# PIC32CK1012SG00048 device description
Architecture: CORTEX-M33; Family: PIC32CK; Series: PIC32CKSG00
Registers are 32-bit, read-write, reset 0x0 unless marked. A register's access mark holds for its fields unless they carry their own. Offsets are from the block's base; [hi:lo] are bit positions; 'fields as' and 'values as' point back to an identical list.

## PCC — Parallel Capture Controller
Instances: PCC 0x45018000
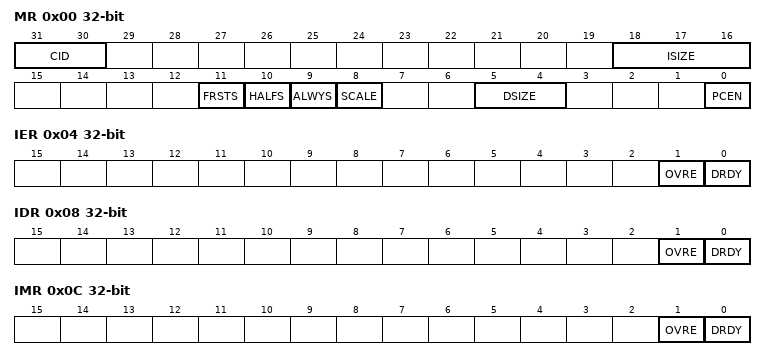
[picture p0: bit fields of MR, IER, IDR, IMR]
0x00 MR — Mode Register
  [31:30] CID — Clear If Disabled
  [18:16] ISIZE — Input Data Size
  [11] FRSTS — First sample
  [10] HALFS — Half Sampling
  [9] ALWYS — Always Sampling
  [8] SCALE — Scale data
  [5:4] DSIZE — Data size
  [0] PCEN — Parallel Capture Enable
0x04 IER wo (atomic set of IMR) — Interrupt Enable Register
  [1] OVRE — Overrun Error Interrupt Enable
  [0] DRDY — Data Ready Interrupt Enable
0x08 IDR wo (atomic clear of IMR) — Interrupt Disable Register
  [1] OVRE — Overrun Error Interrupt Disable
  [0] DRDY — Data Ready Interrupt Disable
0x0C IMR ro — Interrupt Mask Register
  [1] OVRE — Overrun Error Interrupt Mask
  [0] DRDY — Data Ready Interrupt Mask
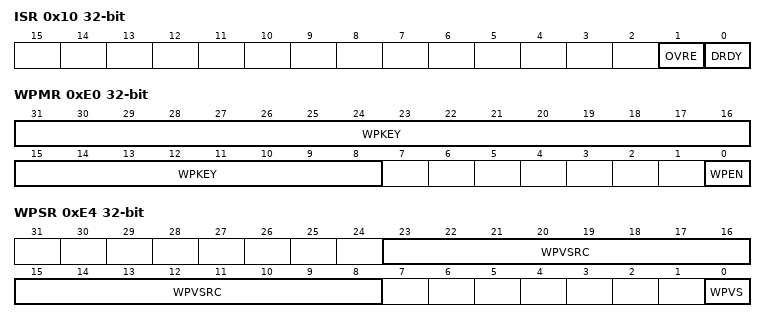
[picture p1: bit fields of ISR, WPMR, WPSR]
0x10 ISR ro — Interrupt Status Register
  [1] OVRE — Overrun Error Interrupt Status
  [0] DRDY — Data Ready Interrupt Status
0x14 RHR ro — Reception Holding Register
  [31:0] RDATA — Reception Data
0xE0 WPMR — Write Protection Mode Register
  [31:8] WPKEY — Write Protection Key
  [0] WPEN — Write Protection Enable
0xE4 WPSR ro — Write Protection Status Register
  [23:8] WPVSRC — Write Protection Violation Status
  [0] WPVS — Write Protection Violation Source

## PM — Power Manager
Instances: PM 0x44006000
0x00 CTRLA 8-bit — Control A
  [2] IORET — I/O Retention
    0=NOIORET (When the device exits the HIBERNATE or BACKUP mode, the I/O line configuration are released.); 1=IORET (When the device exits the HIBERNATE or BACKUP mode, the I/O line configuration are stretched.)
0x01 SLEEPCFG 8-bit reset 0x2 — Sleep Configuration
  [2:0] SLEEPMODE
    2=IDLE (CPU, AHB and APB clocks are OFF); 4=STANDBY (All Clocks are OFF); 5=HIBERNATE (Backup domain is ON as well as some PDRAMs); 6=BACKUP (Only Backup domain is powered ON); 7=OFF (All power domains are powered OFF)
0x04 INTENCLR 8-bit (atomic clear) — Interrupt Enable Clear
  [0] SLEEPRDY — Backup Sleep Mode Entry Ready Enable
0x05 INTENSET 8-bit (atomic set) — Interrupt Enable Set
  [0] SLEEPRDY — Backup Sleep Mode Entry Ready Enable
0x06 INTFLAG 8-bit reset 0x1 (atomic clear) — Interrupt Flag Status and Clear
  [0] SLEEPRDY — Backup Sleep Mode Entry Ready
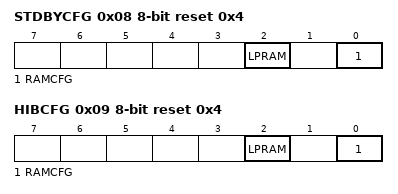
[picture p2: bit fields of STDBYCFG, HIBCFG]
0x08 STDBYCFG 8-bit reset 0x4 — Standby Configuration
  [2] LPRAM — Low Power RAM Enable
  [0] RAMCFG — Ram Configuration
    0=RET (All the RAMs are retained); 1=OFF (Only the first 32K bytes are retained)
0x09 HIBCFG 8-bit reset 0x4 — Hibernate Configuration
  fields as STDBYCFG

## PRM — Boot ROM Controller
Instances: PRM 0x4480A000
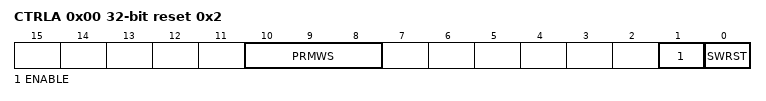
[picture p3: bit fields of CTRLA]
0x00 CTRLA reset 0x2 — CONTROL A REGISTER
  [10:8] PRMWS — ROM ACCESS TIME WAIT STATE
  [1] ENABLE — ENABLE BIT
  [0] SWRST — SOFTWARE RESET BIT

## RSTC — Reset Controller
Instances: RSTC 0x4400A000
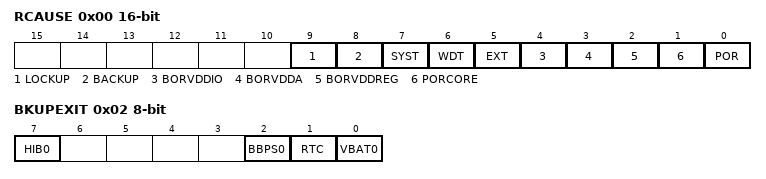
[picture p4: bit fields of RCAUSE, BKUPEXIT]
0x00 RCAUSE 16-bit ro reset not defined — Reset Cause
  [9] LOCKUP — Lockup Reset
  [8] BACKUP — Backup Reset
  [7] SYST — System Reset Request
  [6] WDT — Watchdog Reset
  [5] EXT — External Reset
  [4] BORVDDIO — Brown Out VDDIO Detector Reset
  [3] BORVDDA — Brown Out VDDA Detector Reset
  [2] BORVDDREG — Brown Out VDDREG Detector Reset
  [1] PORCORE — Brown Out CORE Detector Reset
  [0] POR — Power On Reset
0x02 BKUPEXIT 8-bit ro — Backup Exit Source. Implemented only if RSTC_BACKUP_IMPLEMENTED=1
  [7] HIB0 — Hibernate
  [2] BBPS0 — Battery Backup Power Switch
  [1] RTC — Real Timer Counter Interrupt
  [0] VBAT0 — VBAT failure in backup mode
0x04 DBGCTRL — Debug Control
  [0] LCKUPDIS — Lockup Disable

## SQI_DESCRIPTOR — Polaris Serial Quad Interface SIB
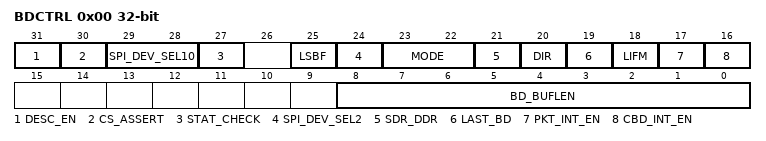
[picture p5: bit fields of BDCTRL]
0x00 BDCTRL reset not defined — Buffer Descriptor Control Register
  [31] DESC_EN — Descriptor Enable
  [30] CS_ASSERT — Chip Select Assert/Deassert
  [29:28] SPI_DEV_SEL10 — SPI Device Select bits 1:0
  [27] STAT_CHECK — Status Check
  [25] LSBF — Data format on SPI Data Lanes
  [24] SPI_DEV_SEL2 — SPI Device Select bit 2
  [23:22] MODE — Based on the mode, the controller has to transmit or receive the data in one or two or 4 lanes
  [21] SDR_DDR — SDR or DDR mode
  [20] DIR — Direction of data transfer.
  [19] LAST_BD — Last Buffer Descriptors.
  [18] LIFM — Indicates last data of the packet.
  [17] PKT_INT_EN — Generate Interrupt after processing the current buffer descriptor, if it is the end of the packet.
  [16] CBD_INT_EN — Generate Interrupt after processing the current buffer descriptor
  [8:0] BD_BUFLEN — Buffer Descriptor Length
0x04 BDSTATUS reset not defined — Buffer Descriptor Status Register
0x08 BDADDR reset not defined — Buffer Descriptor Address Register
0x0C BDNXTPTR reset not defined — Buffer Descriptor Next Pointer Register
